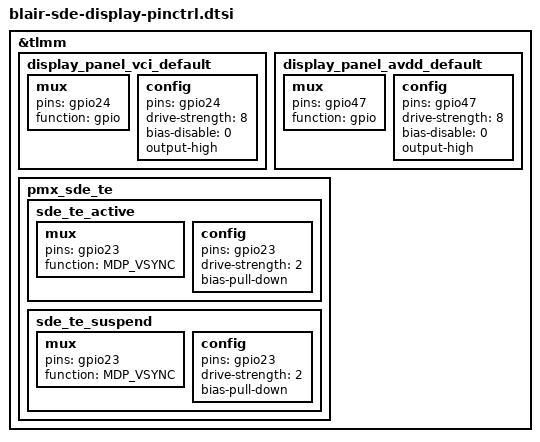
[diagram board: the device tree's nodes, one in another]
&tlmm {
	display_panel_vci_default: display_panel_vci_default {
		mux {
			pins = "gpio24";
			function = "gpio";
		};

		config {
			pins = "gpio24";
			drive-strength = <8>;
			bias-disable = <0>;
			output-high;
		};
	};

	display_panel_avdd_default: display_panel_avdd_default {
		mux {
			pins = "gpio47";
			function = "gpio";
		};

		config {
			pins = "gpio47";
			drive-strength = <8>;
			bias-disable = <0>;
			output-high;
		};
	};

	pmx_sde_te: pmx_sde_te {
		sde_te_active: sde_te_active {
			mux {
				pins = "gpio23";
				function = "MDP_VSYNC";
			};

			config {
				pins = "gpio23";
				drive-strength = <2>;   /* 2 mA */
				bias-pull-down;         /* PULL DOWN */
			};
		};

		sde_te_suspend: sde_te_suspend {
			mux {
				pins = "gpio23";
				function = "MDP_VSYNC";
			};

			config {
				pins = "gpio23";
				drive-strength = <2>;   /* 2 mA */
				bias-pull-down;         /* PULL DOWN */
			};
		};
	};
};
